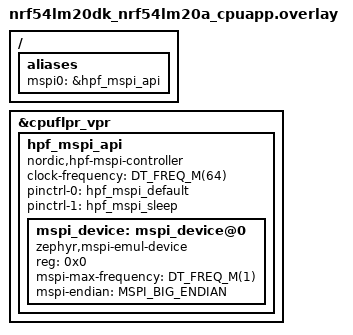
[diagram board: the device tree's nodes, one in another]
/*
 * Copyright (c) 2025 Nordic Semiconductor ASA
 *
 * SPDX-License-Identifier: LicenseRef-Nordic-5-Clause
 */

/ {
	aliases {
		mspi0 = &hpf_mspi_api;
	};
};

&cpuflpr_vpr {
	status = "okay";

	hpf_mspi_api: hpf_mspi_api {
		compatible = "nordic,hpf-mspi-controller";
		#address-cells = <1>;
		#size-cells = <0>;
		clock-frequency = <DT_FREQ_M(64)>;
		pinctrl-0 = <&hpf_mspi_default>;
		pinctrl-1 = <&hpf_mspi_sleep>;
		pinctrl-names = "default", "sleep";
		status = "okay";

		mspi_device: mspi_device@0 {
			status = "okay";
			compatible = "zephyr,mspi-emul-device";
			reg = <0x0>;
			mspi-max-frequency = <DT_FREQ_M(1)>;
			mspi-endian = "MSPI_BIG_ENDIAN";
		};
	};
};
